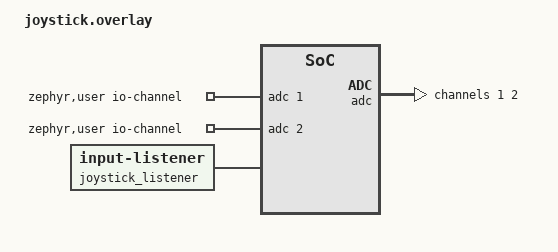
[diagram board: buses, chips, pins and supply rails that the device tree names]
#include <dt-bindings/zmk/keys.h>
#include <behaviors.dtsi>
#include <input/processors.dtsi>
#include <dt-bindings/gpio/nordic-nrf-gpio.h>
#include <dt-bindings/zmk/pointer_config.h>

/* 用户 config 里用 #ifdef SHIELD_JOYSTICK 判断是否选了这个 shield */
#define SHIELD_JOYSTICK


/ {
    zephyr,user {
        io-channels = <&adc 1>, <&adc 2>; 
    };

    /* 2. 定义模拟输入节点 (X 轴与 Y 轴) */
    joystick: analog_input {
        compatible = "zmk,analog-input";
        sampling-hz = <50>;

        idle-sampling-hz = <5>;      /* 3秒无操作后降频到 10Hz */
        idle-timeout-ms = <1000>;    /* 3000ms 判定为静止 Idle */
        /* power-gpios = <&gpio0 8 (GPIO_ACTIVE_HIGH | NRF_GPIO_DRIVE_H0H1)>; */

        /* X 轴子节点 */
        joystick_x {
            io-channels = <&adc 1>; 
            mv-min-max = <1700>;     /* 注意：属性名是短横线 mv-min-max */
            mv-deadzone = <100>;
            evt-type = <2>;          /* INPUT_EV_REL (相对轴事件) */
            input-code = <0>;        /* INPUT_REL_X */
            scale-multiplier = <1>;
            scale-divisor = <70>;
            /* the module sits on the pogo mount turned half a turn (its pins at the pads by the thumb): both axes
             * run the other way */
            invert;
        };

        /* Y 轴子节点 */
        joystick_y {
            io-channels = <&adc 2>; 
            mv-min-max = <1700>;
            mv-deadzone = <100>;
            evt-type = <2>;          /* INPUT_EV_REL */
            input-code = <1>;        /* INPUT_REL_Y */
            scale-multiplier = <1>;
            scale-divisor = <70>;
            invert;                  /* turned half a turn, as x */
        };
    };


    /* the stick's pointer settings: none by default (the axes' invert above turns the module half a turn); the
     * &js_cfg key (ZMK Studio: "Joystick") flips x or y, swaps them or changes the speed, kept over power-off */
    js_pointer: js_pointer {
        compatible = "ergocai,input-processor-pointer-config";
        #input-processor-cells = <0>;
        settings-name = "joystick";
        /* on layer 1 (the stick's push toggles it) the stick scrolls, 32 times slower; a key changes any layer's */
        scroll-layers = <1>;
        scroll-divisor = <32>;
    };

    behaviors {
        js_cfg: js_cfg {
            compatible = "ergocai,behavior-pointer-config";
            #binding-cells = <1>;
            display-name = "Joystick";
            processor = <&js_pointer>;
        };
    };

    joystick_listener {
        compatible = "zmk,input-listener";
        device = <&joystick>;
        input-processors = <&js_pointer>;
    };

};

/* SAADC 通道 1、2: 通道 0 留给 ZMK 的电池分压驱动 (zmk,battery-voltage-divider 固定用通道 0) */
/* 1. 配置 ADC 设备 (按需开启) */
&adc {
    status = "okay";
    #address-cells = <1>;
    #size-cells = <0>;

    adc_joystick_x: channel@1 {
        reg = <1>;
        zephyr,gain = "ADC_GAIN_1_6";
        zephyr,reference = "ADC_REF_INTERNAL";
        zephyr,acquisition-time = <ADC_ACQ_TIME_DEFAULT>;
        zephyr,input-positive = <NRF_SAADC_AIN1>; /* P0.03 */
        zephyr,resolution = <12>;
    };

    adc_joystick_y: channel@2 {
        reg = <2>;
        zephyr,gain = "ADC_GAIN_1_6";
        zephyr,reference = "ADC_REF_INTERNAL";
        zephyr,acquisition-time = <ADC_ACQ_TIME_DEFAULT>;
        zephyr,input-positive = <NRF_SAADC_AIN2>; /* P0.04 */
        zephyr,resolution = <12>;
    };
};

/*
https://docs.nordicsemi.com/r/bundle/ps_nrf52840/page/pin.html

AIN0	A12	P0.02
AIN1	B13	P0.03
AIN2	J1	P0.04
AIN3	K2	P0.05
AIN4	B11	P0.28
AIN5	A10	P0.29
AIN6	B9	P0.30
AIN7	A8	P0.31

*/
